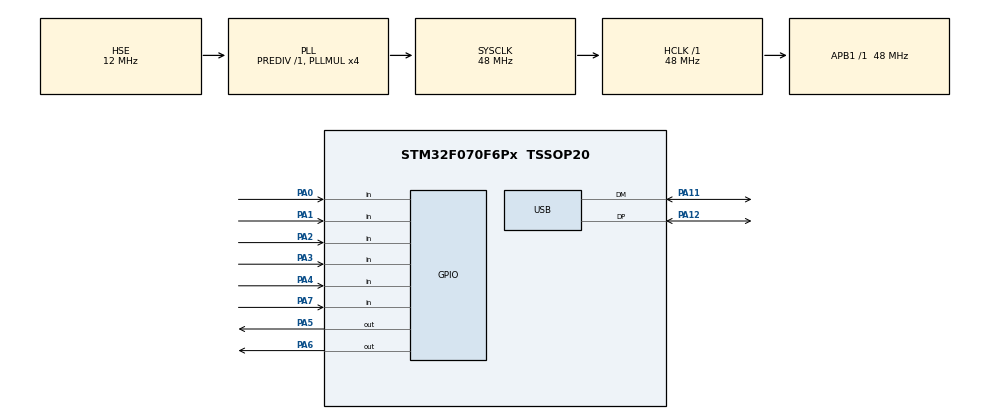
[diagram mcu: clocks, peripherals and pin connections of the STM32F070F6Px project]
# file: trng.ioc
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Mcu.Family=STM32F0
Mcu.Name=STM32F070F6Px
Mcu.Package=TSSOP20
NVIC.TIM14_IRQn=true\:0\:0\:false\:false\:true\:true\:false\:true
NVIC.USB_IRQn=true\:3\:0\:true\:false\:true\:false\:true\:true
PA0.Signal=GPIO_Input
PA1.Signal=GPIO_Input
PA11.Mode=Device
PA11.Signal=USB_DM
PA12.Mode=Device
PA12.Signal=USB_DP
PA13.Mode=Serial_Wire
PA13.Signal=SYS_SWDIO
PA14.Mode=Serial_Wire
PA14.Signal=SYS_SWCLK
PA2.Signal=GPIO_Input
PA3.Signal=GPIO_Input
PA4.Signal=GPIO_Input
PA5.GPIO_Speed=GPIO_SPEED_FREQ_HIGH
PA5.PinState=GPIO_PIN_SET
PA5.Signal=GPIO_Output
PA6.GPIO_ModeDefaultOutputPP=GPIO_MODE_OUTPUT_PP
PA6.GPIO_PuPd=GPIO_NOPULL
PA6.PinState=GPIO_PIN_SET
PA6.Signal=GPIO_Output
PA7.Signal=GPIO_Input
PF0-OSC_IN.Mode=HSE-External-Oscillator
PF0-OSC_IN.Signal=RCC_OSC_IN
PF1-OSC_OUT.Mode=HSE-External-Oscillator
PF1-OSC_OUT.Signal=RCC_OSC_OUT
ProjectManager.HeapSize=0x0
ProjectManager.StackSize=0x400
ProjectManager.TargetToolchain=STM32CubeIDE
RCC.AHBFreq_Value=48000000
RCC.APB1Freq_Value=48000000
RCC.APB1TimFreq_Value=48000000
RCC.HCLKFreq_Value=48000000
RCC.HSE_VALUE=12000000
RCC.PLLMUL=RCC_PLL_MUL4
RCC.SYSCLKFreq_VALUE=48000000
RCC.SYSCLKSource=RCC_SYSCLKSOURCE_PLLCLK
TIM14.Period=599
USB_DEVICE.APP_RX_DATA_SIZE=64
USB_DEVICE.APP_TX_DATA_SIZE=64
USB_DEVICE.CLASS_NAME_FS=CDC
USB_DEVICE.MANUFACTURER_STRING=Toster
USB_DEVICE.PRODUCT_STRING_CDC_FS=Toster TRNG
USB_DEVICE.USBD_SELF_POWERED=0
USB_DEVICE.VirtualMode=Cdc
USB_DEVICE.VirtualModeFS=Cdc_FS
VP_SYS_VS_PINREMAP.Mode=PINREMAP
VP_TIM14_VS_ClockSourceINT.Mode=Enable_Timer
VP_USB_DEVICE_VS_USB_DEVICE_CDC_FS.Mode=CDC_FS
board=custom

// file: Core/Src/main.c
/* USER CODE BEGIN Header */
/**
 ******************************************************************************
 * @file           : main.c
 * @brief          : Main program body
 ******************************************************************************
 * @attention
 *
 * Copyright (c) 2026 STMicroelectronics.
 * All rights reserved.
 *
 * This software is licensed under terms that can be found in the LICENSE file
 * in the root directory of this software component.
 * If no LICENSE file comes with this software, it is provided AS-IS.
 *
 ******************************************************************************
 */
/* USER CODE END Header */
#include "main.h"
#include "usb_device.h"

/* USER CODE BEGIN Includes */
#include "entropy_collector.h"
#include "sender.h"
#include "haptic.h"
/* USER CODE END Includes */

TIM_HandleTypeDef htim14;

void SystemClock_Config(void);
static void MX_GPIO_Init(void);
static void MX_TIM14_Init(void);

int main(void)
{

  /* MCU Configuration--------------------------------------------------------*/

  /* Reset of all peripherals, Initializes the Flash interface and the Systick. */
  HAL_Init();

  /* Configure the system clock */
  SystemClock_Config();

  /* Initialize all configured peripherals */
  MX_GPIO_Init();
  MX_USB_DEVICE_Init();
  MX_TIM14_Init();
  /* USER CODE BEGIN 2 */

  loadConfiguration();
  HAL_TIM_Base_Start_IT(&htim14);
  /* USER CODE END 2 */

  /* Infinite loop */
	while (1) {

		/* USER CODE BEGIN 3 */
		//look also into usbd_cdc.c method CDC_Receive_FS
		//and stm32f0xx_it method TIM14_IRQHandler
		updateCollector();
		updateSender();
		ledUpdate();
	}
  /* USER CODE END 3 */
}

void SystemClock_Config(void)
{
  RCC_OscInitTypeDef RCC_OscInitStruct = {0};
  RCC_ClkInitTypeDef RCC_ClkInitStruct = {0};
  RCC_PeriphCLKInitTypeDef PeriphClkInit = {0};

  /** Initializes the RCC Oscillators according to the specified parameters
  * in the RCC_OscInitTypeDef structure.
  */
  RCC_OscInitStruct.OscillatorType = RCC_OSCILLATORTYPE_HSE;
  RCC_OscInitStruct.HSEState = RCC_HSE_ON;
  RCC_OscInitStruct.PLL.PLLState = RCC_PLL_ON;
  RCC_OscInitStruct.PLL.PLLSource = RCC_PLLSOURCE_HSE;
  RCC_OscInitStruct.PLL.PLLMUL = RCC_PLL_MUL4;
  RCC_OscInitStruct.PLL.PREDIV = RCC_PREDIV_DIV1;
  if (HAL_RCC_OscConfig(&RCC_OscInitStruct) != HAL_OK)
  {
    Error_Handler();
  }

  /** Initializes the CPU, AHB and APB buses clocks
  */
  RCC_ClkInitStruct.ClockType = RCC_CLOCKTYPE_HCLK|RCC_CLOCKTYPE_SYSCLK
                              |RCC_CLOCKTYPE_PCLK1;
  RCC_ClkInitStruct.SYSCLKSource = RCC_SYSCLKSOURCE_PLLCLK;
  RCC_ClkInitStruct.AHBCLKDivider = RCC_SYSCLK_DIV1;
  RCC_ClkInitStruct.APB1CLKDivider = RCC_HCLK_DIV1;

  if (HAL_RCC_ClockConfig(&RCC_ClkInitStruct, FLASH_LATENCY_1) != HAL_OK)
  {
    Error_Handler();
  }
  PeriphClkInit.PeriphClockSelection = RCC_PERIPHCLK_USB;
  PeriphClkInit.UsbClockSelection = RCC_USBCLKSOURCE_PLL;

  if (HAL_RCCEx_PeriphCLKConfig(&PeriphClkInit) != HAL_OK)
  {
    Error_Handler();
  }
}

static void MX_TIM14_Init(void)
{

  /* USER CODE BEGIN TIM14_Init 1 */
  //Time constants:
	// 60kHz - htim14.Init.Period = 799;
	// 70kHz - htim14.Init.Period = 685;
	// 80kHz - htim14.Init.Period = 599;
	// 90kHz - htim14.Init.Period = 532;
	// 100kHz - htim14.Init.Period = 479;
  /* USER CODE END TIM14_Init 1 */
  htim14.Instance = TIM14;
  htim14.Init.Prescaler = 0;
  htim14.Init.CounterMode = TIM_COUNTERMODE_UP;
  htim14.Init.Period = 479;
  htim14.Init.ClockDivision = TIM_CLOCKDIVISION_DIV1;
  htim14.Init.AutoReloadPreload = TIM_AUTORELOAD_PRELOAD_DISABLE;
  if (HAL_TIM_Base_Init(&htim14) != HAL_OK)
  {
    Error_Handler();
  }

}

static void MX_GPIO_Init(void)
{
  GPIO_InitTypeDef GPIO_InitStruct = {0};

  /* GPIO Ports Clock Enable */
  __HAL_RCC_GPIOF_CLK_ENABLE();
  __HAL_RCC_GPIOA_CLK_ENABLE();

  /*Configure GPIO pin Output Level */
  HAL_GPIO_WritePin(GPIOA, GPIO_PIN_5|GPIO_PIN_6, GPIO_PIN_SET);

  /*Configure GPIO pins : PA0 PA1 PA2 PA3
                           PA4 PA7 */
  GPIO_InitStruct.Pin = GPIO_PIN_0|GPIO_PIN_1|GPIO_PIN_2|GPIO_PIN_3
                          |GPIO_PIN_4|GPIO_PIN_7;
  GPIO_InitStruct.Mode = GPIO_MODE_INPUT;
  GPIO_InitStruct.Pull = GPIO_NOPULL;
  HAL_GPIO_Init(GPIOA, &GPIO_InitStruct);

  /*Configure GPIO pin : PA5 */
  GPIO_InitStruct.Pin = GPIO_PIN_5;
  GPIO_InitStruct.Mode = GPIO_MODE_OUTPUT_PP;
  GPIO_InitStruct.Pull = GPIO_NOPULL;
  GPIO_InitStruct.Speed = GPIO_SPEED_FREQ_HIGH;
  HAL_GPIO_Init(GPIOA, &GPIO_InitStruct);

  /*Configure GPIO pin : PA6 */
  GPIO_InitStruct.Pin = GPIO_PIN_6;
  GPIO_InitStruct.Mode = GPIO_MODE_OUTPUT_PP;
  GPIO_InitStruct.Pull = GPIO_NOPULL;
  GPIO_InitStruct.Speed = GPIO_SPEED_FREQ_LOW;
  HAL_GPIO_Init(GPIOA, &GPIO_InitStruct);

}

void Error_Handler(void)
{
	__disable_irq();
	while (1) {
	}
}
